# NUC1xx_registers register map
File version: 0.1
CPU: 
Registers are 32-bit, read-write, reset 0x0 unless marked. A register's access mark holds for its fields unless they carry their own. Offsets are from the block's base; [hi:lo] are bit positions; lines under a group give offsets from that group; {n}, {i} and the like mark numbered series; <NAME> marks a mode.

## CLK — Registers group
Base 0x50000200
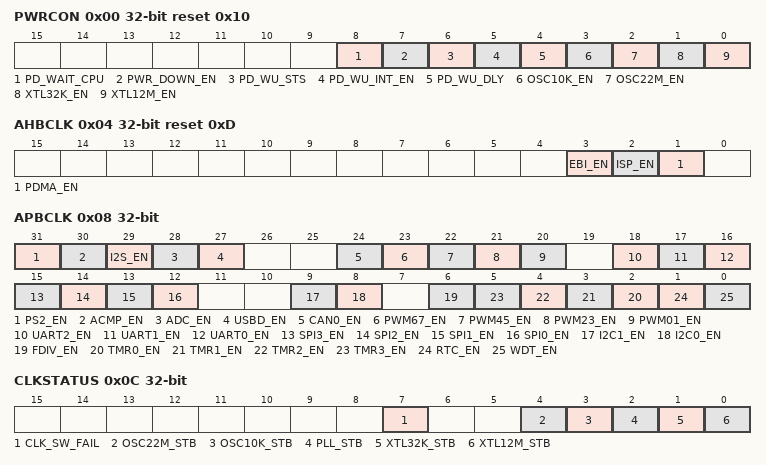
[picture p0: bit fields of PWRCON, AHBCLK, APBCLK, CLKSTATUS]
0x00 PWRCON reset 0x10 (reset mask 0xFFFFFFF0) — System Power Down Control Register
  [8] PD_WAIT_CPU — This bit control the power down entry condition (write-protection bit) 1 = Chip enter power down mode when the both PWR_DOWN_EN bit is set to 1 and CPU run WFI instruction. 0 = Chip entry power down mode when the PWR_DOWN_EN bit is set to 1.
  [7] PWR_DOWN_EN — System power down enable bit (write-protection bit) When CPU sets this bit "1" the chip power down mode is enabled, and chip power-down behavior will depends on the PD_WAIT_CPU bit. (a) If the PD_WAIT_CPU is "0", then the chip enters power down mode immediately after the PWR_DOWN_EN bit set. (b) if the PD_WAIT_CPU is "1", then the chip keeps active till the CPU sleep mode is also active and then the chip enters power down mode. When chip wakes up from power down mode, this bit is auto cleared. Users need to set this bit again for next power down. When in power down mode, external 4~24 MHz crystal and the internal 22.1184 MHz oscillator will be disabled in this mode, but the external 32 kHz crystal and internal 10 kHz oscillator are not controlled by power down mode. When in power down mode, the PLL and system clock are disabled, and ignored the clock source selection. The clocks of peripheral are not controlled by power down mode, if the peripheral clock source is from 32 kHz crystal or the 10 kHz oscillator. 1 = Chip enter the power down mode instant or wait CPU sleep command WFI. 0 = Chip operate in normal mode or CPU in idle mode (sleep mode) because of WFI command.
  [6] PD_WU_STS write-1-clears — Power down mode wake up interrupt status Set by "power down wake up", it indicates that resume from power down mode The flag is set if the GPIO, USB, UART, WDT, CAN, ACMP, BOD or RTC wakeup occurred Write 1 to clear the bit Note: This bit is working only if PD_WU_INT_EN (PWRCON[5]) set to 1.
  [5] PD_WU_INT_EN — Power down mode wake up Interrupt enable (write-protection bit) 0 = Disable 1 = Enable. The interrupt will occur when both PD_WU_STS and PD_WU_INT_EN are high.
  [4] PD_WU_DLY — Enable the wake up delay counter (write-protection bit) When the chip wakes up from power down mode, the clock control will delay certain clock cycles to wait system clock stable. The delayed clock cycle is 4096 clock cycles when chip work at external 4~24 MHz crystal, and 256 clock cycles when chip work at internal 22.1184 MHz oscillator. 1 = Enable clock cycles delay 0 = Disable clock cycles delay
  [3] OSC10K_EN — Internal 10KHz Oscillator Enable (write-protection bit) 1 = Enable 10KHz Oscillation 0 = Disable 10KHz Oscillation
  [2] OSC22M_EN — Internal 22.1184MHz Oscillator Enable (write-protection bit) 1 = Enable 22.1184MHz Oscillation 0 = Disable 22.1184MHz Oscillation
  [1] XTL32K_EN — External 32.768 KHz Crystal Enable (write-protection bit) 1 = Enable external 32.768 kHz Crystal (Normal operation) 0 = Disable external 32.768 kHz Crystal
  [0] XTL12M_EN — External 4~24 MHz Crystal Enable (write-protection bit) The bit default value is set by flash controller user configuration register config0 [26:24]. When the default clock source is from external 4~24 MHz crystal, this bit is set to 1 automatically 1 = Enable external 4~24 MHz crystal 0 = Disable external 4~24 MHz crystal
0x04 AHBCLK reset 0xD — AHB Devices Clock Enable Control Register
  [3] EBI_EN — EBI Controller Clock Enable Control (Low Density Only) 1 = Enable the EBI engine clock. 0 = Disable the EBI engine clock.
  [2] ISP_EN — Flash ISP Controller Clock Enable Control. 1 = Enable the Flash ISP engine clock. 0 = Disable the Flash ISP engine clock.
  [1] PDMA_EN — PDMA Controller Clock Enable Control. 1 = Enable the PDMA engine clock. 0 = Disable the PDMA engine clock.
0x08 APBCLK (reset mask 0xFFFFFFF0) — APB Devices Clock Enable Control Register
  [31] PS2_EN — PS2 Clock Enable. 1 = Enable PS2 clock 0 = Disable PS2 clock
  [30] ACMP_EN — Analog Comparator Clock Enable. 1 = Enable the Analog Comparator Clock 0 = Disable the Analog Comparator Clock
  [29] I2S_EN — I2S Clock Enable 1 = Enable I2S Clock 0 = Disable I2S Clock
  [28] ADC_EN — Analog-Digital-Converter (ADC) Clock Enable. 1 = Enable ADC clock 0 = Disable ADC clock
  [27] USBD_EN — USB 2.0 FS Device Controller Clock Enable 1 = Enable USB clock 0 = Disable USB clock
  [24] CAN0_EN — CAN Bus Controller-0 Clock Enable 1 = Enable CAN0 clock 0 = Disable CAN0 clock
  [23] PWM67_EN — PWM_67 Clock Enable.(Medium Density Only) 1 = Enable PWM67 clock 0 = Disable PWM67 clock
  [22] PWM45_EN — PWM_45 Clock Enable.(Medium Density Only) 1 = Enable PWM45 clock 0 = Disable PWM45 clock
  [21] PWM23_EN — PWM_23 Clock Enable. 1 = Enable PWM23 clock 0 = Disable PWM23 clock
  [20] PWM01_EN — PWM_01 Clock Enable. 1 = Enable PWM01 clock 0 = Disable PWM01 clock
  [18] UART2_EN — UART2 Clock Enable.(Medium Density Only) 1 = Enable UART2 clock 0 = Disable UART2 clock
  [17] UART1_EN — UART1 Clock Enable. 1 = Enable UART1 clock 0 = Disable UART1 clock
  [16] UART0_EN — UART0 Clock Enable. 1 = Enable UART0 clock 0 = Disable UART0 clock
  [15] SPI3_EN — SPI3 Clock Enable. (Medium Density Only) 1 = Enable SPI3 Clock 0 = Disable SPI3 Clock
  [14] SPI2_EN — SPI2 Clock Enable. (Medium Density Only) 1 = Enable SPI2 Clock 0 = Disable SPI2 Clock
  [13] SPI1_EN — SPI1 Clock Enable. 1 = Enable SPI1 Clock 0 = Disable SPI1 Clock
  [12] SPI0_EN — SPI0 Clock Enable. 1 = Enable SPI0 Clock 0 = Disable SPI0 Clock
  [9] I2C1_EN — I2C1 Clock Enable. 1 = Enable I2C1 Clock 0 = Disable I2C1 Clock
  [8] I2C0_EN — I2C0 Clock Enable . 1 = Enable I2C0 Clock 0 = Disable I2C0 Clock
  [6] FDIV_EN — Frequency Divider Output Clock Enable 1 = Enable FDIV Clock 0 = Disable FDIV Clock
  [n+2] TMR{n}_EN (n=0..3) — Timer{n} Clock Enable 1 = Enable Timer{n} Clock 0 = Disable Timer{n} Clock
  [1] RTC_EN — Real-Time-Clock APB interface Clock Enable. This bit is used to control the RTC APB clock only, The RTC engine clock source is from the 32.768KHz crystal. 1 = Enable RTC Clock 0 = Disable RTC Clock
  [0] WDT_EN — Watch Dog Timer Clock Enable (write-protection bit) This bit is the protected bit. It means programming this needs to write "59h", "16h", "88h" to address 0x5000_0100 to disable register protection. Reference the register REGWRPROT at address GCR_BA+0x100. The bit default value is set by flash controller. User configuration register config0 bit[31] 1 = Enable Watchdog Timer Clock 0 = Disable Watchdog Timer Clock
0x0C CLKSTATUS (reset mask 0xFFFFFF00) — Clock status monitor Register
  [7] CLK_SW_FAIL write-1-clears — Clock switching fail flag 1 = Clock switching failure 0 = Clock switching success This bit is updated when software switches system clock source. If switch target clock is stable, this bit will be set to 1'b0. If switch target clock is not stable, this bit will be set to 1'b1. Write 1 to clear the bit to zero
  [4] OSC22M_STB ro — OSC22M clock source stable flag 1 = OSC22M clock is stable 0 = OSC22M clock is not stable or disabled This is read only bit
  [3] OSC10K_STB ro — OSC10K clock source stable flag 1 = OSC10K clock is stable 0 = OSC10K clock is not stable or disabled This is read only bit
  [2] PLL_STB ro — PLL clock source stable flag 1 = PLL clock is stable 0 = PLL clock is not stable or disabled This is read only bit
  [1] XTL32K_STB ro — XTL32K clock source stable flag 1 = XTL32K clock is stable 0 = XTL32K clock is not stable or disabled This is read only bit
  [0] XTL12M_STB ro — XTL12M clock source stable flag 1 = XTL12M clock is stable 0 = XTL12M clock is not stable or disabled This is read only bit
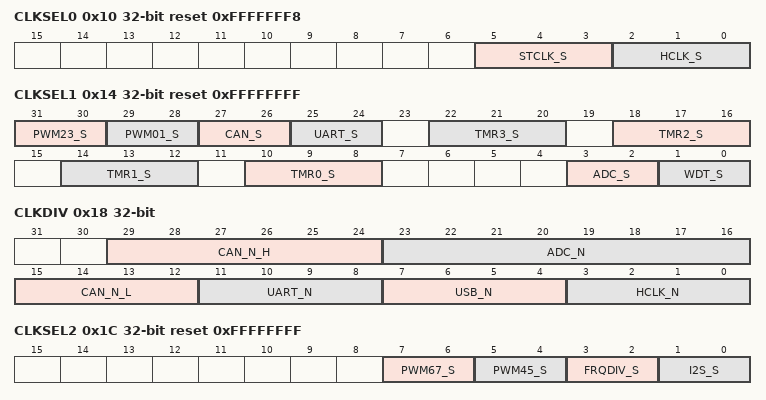
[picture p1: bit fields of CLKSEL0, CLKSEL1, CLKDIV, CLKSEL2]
0x10 CLKSEL0 reset 0xFFFFFFF8 (reset mask 0xFFFFFFF8) — Clock Source Select Control Register 0
  [5:3] STCLK_S — Cortex_M0 SysTick clock source select (write-protection bits) If SYST_CSR[2]=0, SysTick uses listed clock source below These bits are protected bit. It means programming this bit needs to write "59h", "16h", "88h" to address 0x5000_0100 to disable register protection. Reference the register REGWRPROT at address GCR_BA+0x100. 000 = clock source from 4~24 MHz crystal clock 001 = Clock source from external 32.768 kHz crystal clock 010 = clock source from 12MHz crystal clock / 2 011 = clock source from HCLK / 2 1xx = Clock source from internal 22.1184 MHz oscillator clock / 2
  [2:0] HCLK_S — HCLK clock source select (write-protection bits) Note: 1. Before clock switching, the related clock sources (both pre-select and new-select) must be turn on 2. The 3-bit default value is reloaded from the value of CFOSC (Config0[26:24]) in user configuration register of Flash controller by any reset. Therefore the default value is either 000b or 111b. 3. These bits are protected bit, It means programming this bit needs to write "59h", "16h", "88h" to address 0x5000_0100 to disable register protection. Reference the register REGWRPROT at address GCR_BA+0x100. 000 = Clock source from external 4~24 MHz crystal clock 001 = Clock source from external 32.768 kHz crystal clock 010 = Clock source from PLL clock 011 = Clock source from internal 10 kHz oscillator clock 111 = Clock source from internal 22.1184 MHz oscillator clock Others = reserved
0x14 CLKSEL1 reset 0xFFFFFFFF — Clock Source Select Control Register 1
  [31:30] PWM23_S — PWM2 and PWM3 clock source select PWM2 and PWM3 uses the same Engine clock source, both of them use the same prescaler. 00 = Clock source from external 4~24 MHz crystal clock. 01 = Clock source from external 32.768 kHz crystal clock. 10 = Clock source from HCLK. 11 = Clock source from internal 22.1184 MHz oscillator clock.
  [29:28] PWM01_S — PWM0 and PWM1 clock source select PWM0 and PWM1 uses the same Engine clock source, both of them use the same prescaler. 00 = Clock source from external 4~24 MHz crystal clock. 01 = Clock source from external 32.768 kHz crystal clock. 10 = Clock source from HCLK. 11 = Clock source from internal 22.1184 MHz oscillator clock.
  [27:26] CAN_S — CAN clock source select 00 = Clock source from external 4~24 MHz crystal clock. 01 = Clock source from PLL clock. 1x = Clock source from internal 22.1184 MHz oscillator clock.
  [25:24] UART_S — UART clock source select. 00 = Clock source from external 4~24 MHz crystal clock. 01 = Clock source from PLL clock. 1x = Clock source from internal 22.1184 MHz oscillator clock.
  [4n+10:4n+8] TMR{n}_S (n=0..3) — TIMER{n} clock source select. 000 = Clock source from external 4~24 MHz crystal clock. 001 = Clock source from external 32.768 kHz crystal clock. 010 = Clock source from HCLK. 011 = Clock source from external trigger. 1xx = Clock source from internal 22.1184 MHz oscillator clock.
  [3:2] ADC_S — ADC clock source select 00 = Clock source from external 4~24 MHz crystal clock. 01 = clock source from PLL clock 1x = Clock source from internal 22.1184 MHz oscillator clock.
  [1:0] WDT_S — Watchdog Timer clock source select (write-protection bits) These bits are protected bit, program this need to write "59h", "16h", "88h" to address 0x5000_0100 to disable register protection. Reference the register REGWRPROT at address GCR_BA+0x100. 00 = Clock source from external 4~24 MHz crystal clock. 01 = Reserved 10 = Clock source from HCLK/2048 clock. 11 = Clock source from internal 10 kHz oscillator clock.
0x18 CLKDIV — Clock Divider Number Register
  [29:24] CAN_N_H — CAN clock divide number from CAN clock source (Low Density Only) The CAN clock frequency = (CAN clock source frequency ) / (CAN_N + 1) Which CAN_N = 16 * CAN_N_H + CAN_N_L
  [23:16] ADC_N — ADC clock divide number from ADC clock source The ADC clock frequency = (ADC engine clock source frequency ) / (ADC_N + 1)
  [15:12] CAN_N_L — CAN clock divide number from CAN clock source The CAN clock frequency = (CAN clock source frequency ) / (CAN_N + 1) Which CAN_N = 16 * CAN_N_H + CAN_N_L
  [11:8] UART_N — UART clock divide number from UART clock source The UART clock frequency = (UART clock source frequency ) / (UART_N + 1)
  [7:4] USB_N — USB clock divide number from PLL clock The USB clock frequency = (PLL frequency ) / (USB_N + 1)
  [3:0] HCLK_N — HCLK clock divide number from HCLK clock source The HCLK clock frequency = (HCLK clock source frequency) / (HCLK_N + 1)
0x1C CLKSEL2 reset 0xFFFFFFFF — Clock Source Select Control Register 2
  [7:6] PWM67_S — PWM6 and PWM7 Clock Source Select.(Medium Density Only) PWM6 and PWM7 used the same Engine clock source, both of them use the same prescaler. 00 = Clock source from external 4~24 MHz crystal clock. 01 = Clock source from external 32.768 kHz crystal clock. 10 = Clock source from HCLK. 11 = Clock source from internal 22.1184 MHz oscillator clock.
  [5:4] PWM45_S — PWM4 and PWM5 Clock Source Select.(Medium Density Only) PWM4 and PWM5 used the same Engine clock source, both of them use the same prescaler. 00 = Clock source from external 4~24 MHz crystal clock. 01 = Clock source from external 32.768 kHz crystal clock. 10 = Clock source from HCLK. 11 = Clock source from internal 22.1184 MHz oscillator clock.
  [3:2] FRQDIV_S — Clock Divider Clock Source Select. 00 = Clock source from external 4~24 MHz crystal clock. 01 = Clock source from external 32.768 kHz crystal clock. 10 = Clock source from HCLK. 11 = Clock source from internal 22.1184 MHz oscillator clock.
  [1:0] I2S_S — I2S clock source select. 00 = Clock source from external 4~24 MHz crystal clock. 01 = Clock source from PLL clock. 10 = Clock source from HCLK. 11 = Clock source from internal 22.1184 MHz oscillator clock.
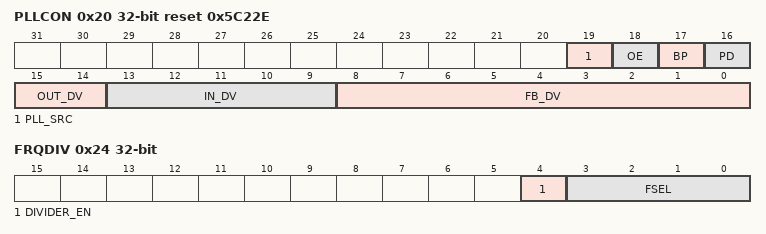
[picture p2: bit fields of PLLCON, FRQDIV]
0x20 PLLCON reset 0x5C22E — PLL Control Register
  [19] PLL_SRC — PLL Source Clock Select 1 = PLL source clock from 22.1184 MHz oscillator 0 = PLL source clock from 4~24 MHz crystal
  [18] OE — PLL OE (FOUT enable) pin Control 0 = PLL FOUT enable 1 = PLL FOUT is fixed low
  [17] BP — PLL Bypass Control 0 = PLL is in normal mode (default) 1 = PLL clock output is same as clock input (XTALin)
  [16] PD — Power Down Mode. If set the IDLE bit "1" in PWRCON register, the PLL will enter power down mode too 0 = PLL is in normal mode 1 = PLL is in power-down mode(default)
  [15:14] OUT_DV — PLL Output Divider Control Pins Refer to the formulas below the table. (Table is the same as FB_DV).
  [13:9] IN_DV — PLL Input Divider Control Pins Refer to the formulas below the table. (Table is the same as FB_DV).
  [8:0] FB_DV — PLL Feedback Divider Control Pins Refer to the formulas below the table. FOUT = FIN x NF/NR x 1/NO Constrain: 1. 3.2MHz < FIN < 150MHz 2. 800KHz < FIN/(2xNR) < 8MHz 3. 100MHz < FCO = FINxNF/NR < 200MHz , 120M < FCO is preferred. Symbol Description FOUT Output Clock Frequency FIN Input (Reference) Clock Frequency NR Input Divider (IN_DV + 2) NF Feedback Divider (FB_DV + 2) NO OUT_DV = "00":NO = 1 OUT_DV = "01":NO = 2 OUT_DV = "10":NO = 2 OUT_DV = "11":NO = 4
0x24 FRQDIV — Frequency Divider Control Register
  [4] DIVIDER_EN — Frequency Divider Enable Bit 0 = Disable Frequency Divider 1 = Enable Frequency Divider
  [3:0] FSEL — Divider Output Frequency Selection Bits The formula of output frequency is Fout = Fin/(2^(N+1)), Fin is the input clock frequency. Fout is the frequency of divider output clock. N is the 4-bit value of FSEL[3:0].
